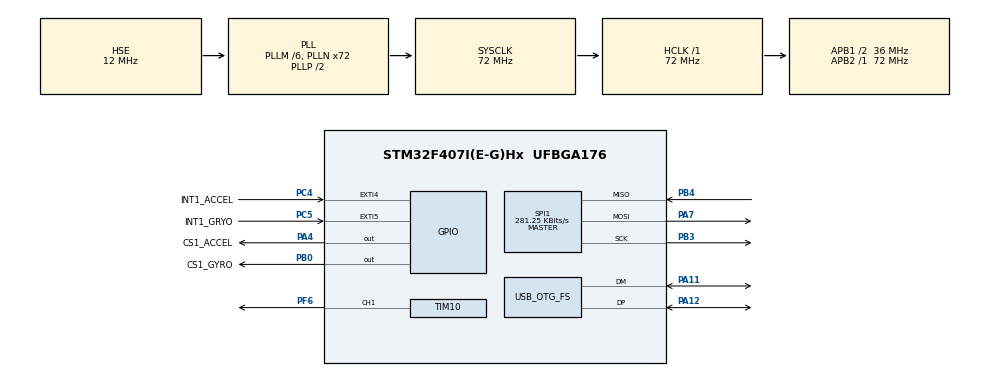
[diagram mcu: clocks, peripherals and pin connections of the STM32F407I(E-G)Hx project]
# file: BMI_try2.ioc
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Dma.Request0=SPI1_RX
Dma.Request1=SPI1_TX
Dma.SPI1_RX.0.Direction=DMA_PERIPH_TO_MEMORY
Dma.SPI1_RX.0.FIFOMode=DMA_FIFOMODE_DISABLE
Dma.SPI1_RX.0.Instance=DMA2_Stream2
Dma.SPI1_RX.0.MemDataAlignment=DMA_MDATAALIGN_BYTE
Dma.SPI1_RX.0.MemInc=DMA_MINC_ENABLE
Dma.SPI1_RX.0.Mode=DMA_NORMAL
Dma.SPI1_RX.0.PeriphDataAlignment=DMA_PDATAALIGN_BYTE
Dma.SPI1_RX.0.PeriphInc=DMA_PINC_DISABLE
Dma.SPI1_RX.0.Priority=DMA_PRIORITY_VERY_HIGH
Dma.SPI1_TX.1.Direction=DMA_MEMORY_TO_PERIPH
Dma.SPI1_TX.1.FIFOMode=DMA_FIFOMODE_DISABLE
Dma.SPI1_TX.1.Instance=DMA2_Stream3
Dma.SPI1_TX.1.MemDataAlignment=DMA_MDATAALIGN_BYTE
Dma.SPI1_TX.1.MemInc=DMA_MINC_ENABLE
Dma.SPI1_TX.1.Mode=DMA_NORMAL
Dma.SPI1_TX.1.PeriphDataAlignment=DMA_PDATAALIGN_BYTE
Dma.SPI1_TX.1.PeriphInc=DMA_PINC_DISABLE
Dma.SPI1_TX.1.Priority=DMA_PRIORITY_HIGH
FREERTOS.Tasks01=defaultTask,0,128,StartDefaultTask,Default,NULL,Dynamic,NULL,NULL;Usb_task,3,3072,usb_task,As weak,NULL,Dynamic,NULL,NULL
Mcu.Family=STM32F4
Mcu.Name=STM32F407I(E-G)Hx
Mcu.Package=UFBGA176
NVIC.DMA2_Stream2_IRQn=true\:5\:0\:false\:false\:true\:true\:false\:true\:true
NVIC.DMA2_Stream3_IRQn=true\:5\:0\:false\:false\:true\:true\:false\:true\:true
NVIC.OTG_FS_IRQn=true\:5\:0\:false\:false\:true\:true\:false\:true\:true
NVIC.PriorityGroup=NVIC_PRIORITYGROUP_4
NVIC.TIM1_UP_TIM10_IRQn=true\:15\:0\:false\:false\:true\:false\:false\:true\:true
NVIC.TimeBase=TIM1_UP_TIM10_IRQn
NVIC.TimeBaseIP=TIM1
PA11.Mode=Device_Only
PA11.Signal=USB_OTG_FS_DM
PA12.Mode=Device_Only
PA12.Signal=USB_OTG_FS_DP
PA13.Mode=Serial_Wire
PA13.Signal=SYS_JTMS-SWDIO
PA14.Mode=Serial_Wire
PA14.Signal=SYS_JTCK-SWCLK
PA4.GPIO_Label=CS1_ACCEL
PA4.GPIO_PuPd=GPIO_PULLUP
PA4.GPIO_Speed=GPIO_SPEED_FREQ_HIGH
PA4.PinState=GPIO_PIN_SET
PA4.Signal=GPIO_Output
PA7.Mode=Full_Duplex_Master
PA7.Signal=SPI1_MOSI
PB0.GPIO_Label=CS1_GYRO
PB0.GPIO_PuPd=GPIO_PULLUP
PB0.GPIO_Speed=GPIO_SPEED_FREQ_HIGH
PB0.PinState=GPIO_PIN_SET
PB0.Signal=GPIO_Output
PB3.Mode=Full_Duplex_Master
PB3.Signal=SPI1_SCK
PB4.Mode=Full_Duplex_Master
PB4.Signal=SPI1_MISO
PC4.GPIO_Label=INT1_ACCEL
PC4.GPIO_PuPd=GPIO_PULLUP
PC4.Signal=GPXTI4
PC5.GPIO_Label=INT1_GRYO
PC5.GPIO_PuPd=GPIO_PULLUP
PC5.Signal=GPXTI5
PF6.GPIO_PuPd=GPIO_PULLUP
PF6.GPIO_Speed=GPIO_SPEED_FREQ_HIGH
PF6.Signal=S_TIM10_CH1
PH0-OSC_IN.Mode=HSE-External-Oscillator
PH0-OSC_IN.Signal=RCC_OSC_IN
PH1-OSC_OUT.Mode=HSE-External-Oscillator
PH1-OSC_OUT.Signal=RCC_OSC_OUT
ProjectManager.HeapSize=0x200
ProjectManager.StackSize=0x400
ProjectManager.TargetToolchain=MDK-ARM V5.32
RCC.48MHZClocksFreq_Value=48000000
RCC.AHBFreq_Value=72000000
RCC.APB1CLKDivider=RCC_HCLK_DIV2
RCC.APB1Freq_Value=36000000
RCC.APB1TimFreq_Value=72000000
RCC.APB2Freq_Value=72000000
RCC.APB2TimFreq_Value=72000000
RCC.CortexFreq_Value=72000000
RCC.HCLKFreq_Value=72000000
RCC.HSE_VALUE=12000000
RCC.HSI_VALUE=16000000
RCC.LSE_VALUE=32768
RCC.PLLM=6
RCC.PLLN=72
RCC.PLLQ=3
RCC.SYSCLKFreq_VALUE=72000000
RCC.SYSCLKSource=RCC_SYSCLKSOURCE_PLLCLK
RCC.VCOOutputFreq_Value=144000000
SH.S_TIM10_CH1.0=TIM10_CH1,PWM Generation1 CH1
SPI1.BaudRatePrescaler=SPI_BAUDRATEPRESCALER_256
SPI1.CLKPhase=SPI_PHASE_2EDGE
SPI1.CLKPolarity=SPI_POLARITY_HIGH
SPI1.CalculateBaudRate=281.25 KBits/s
SPI1.Direction=SPI_DIRECTION_2LINES
SPI1.Mode=SPI_MODE_MASTER
SPI1.VirtualType=VM_MASTER
TIM10.Channel=TIM_CHANNEL_1
TIM10.Period=4999
USB_DEVICE.CLASS_NAME_FS=CDC
USB_DEVICE.MANUFACTURER_STRING-CDC_FS=RM
USB_DEVICE.PID_CDC_FS=0x514
USB_DEVICE.VID-CDC_FS=0x114
USB_DEVICE.VirtualMode-CDC_FS=Cdc
USB_DEVICE.VirtualModeFS=Cdc_FS
USB_OTG_FS.VirtualMode=Device_Only
VP_FREERTOS_VS_CMSIS_V1.Mode=CMSIS_V1
VP_SYS_VS_tim1.Mode=TIM1
VP_TIM10_VS_ClockSourceINT.Mode=Enable_Timer
VP_USB_DEVICE_VS_USB_DEVICE_CDC_FS.Mode=CDC_FS
board=custom

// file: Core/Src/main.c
/* USER CODE BEGIN Header */
/**
  ******************************************************************************
  * @file           : main.c
  * @brief          : Main program body
  ******************************************************************************
  * @attention
  *
  * Copyright (c) 2026 STMicroelectronics.
  * All rights reserved.
  *
  * This software is licensed under terms that can be found in the LICENSE file
  * in the root directory of this software component.
  * If no LICENSE file comes with this software, it is provided AS-IS.
  *
  ******************************************************************************
  */
/* USER CODE END Header */
#include "main.h"
#include "cmsis_os.h"
#include "dma.h"
#include "spi.h"
#include "tim.h"
#include "usb_device.h"
#include "gpio.h"

/* USER CODE BEGIN Includes */
#include "bsp_usb.h"
#include "queue.h"
#include "BMI088Middleware.h"
#include "struct_typedef.h"
#include "BMI088driver.h"
#include "usbd_cdc_if.h"
/* USER CODE END Includes */

void SystemClock_Config(void);
void MX_FREERTOS_Init(void);
/* USER CODE BEGIN PFP */
uint8_t usb_tx_buf[128];
uint8_t usb_rx_buf[128];
/* USER CODE END PFP */

int main(void)
{

  /* MCU Configuration--------------------------------------------------------*/

  /* Reset of all peripherals, Initializes the Flash interface and the Systick. */
  HAL_Init();

  /* Configure the system clock */
  SystemClock_Config();

  /* Initialize all configured peripherals */
  MX_GPIO_Init();
  MX_DMA_Init();
  MX_SPI1_Init();
  MX_TIM10_Init();
  /* USER CODE BEGIN 2 */
	usb_init();
 MX_USB_DEVICE_Init();
  /* USER CODE END 2 */

  /* Call init function for freertos objects (in cmsis_os2.c) */
  MX_FREERTOS_Init();

  /* Start scheduler */
  osKernelStart();

  /* We should never get here as control is now taken by the scheduler */

  /* Infinite loop */
  while (1)
  {

  }
}

void SystemClock_Config(void)
{
  RCC_OscInitTypeDef RCC_OscInitStruct = {0};
  RCC_ClkInitTypeDef RCC_ClkInitStruct = {0};

  /** Configure the main internal regulator output voltage
  */
  __HAL_RCC_PWR_CLK_ENABLE();
  __HAL_PWR_VOLTAGESCALING_CONFIG(PWR_REGULATOR_VOLTAGE_SCALE1);

  /** Initializes the RCC Oscillators according to the specified parameters
  * in the RCC_OscInitTypeDef structure.
  */
  RCC_OscInitStruct.OscillatorType = RCC_OSCILLATORTYPE_HSE;
  RCC_OscInitStruct.HSEState = RCC_HSE_ON;
  RCC_OscInitStruct.PLL.PLLState = RCC_PLL_ON;
  RCC_OscInitStruct.PLL.PLLSource = RCC_PLLSOURCE_HSE;
  RCC_OscInitStruct.PLL.PLLM = 6;
  RCC_OscInitStruct.PLL.PLLN = 72;
  RCC_OscInitStruct.PLL.PLLP = RCC_PLLP_DIV2;
  RCC_OscInitStruct.PLL.PLLQ = 3;
  if (HAL_RCC_OscConfig(&RCC_OscInitStruct) != HAL_OK)
  {
    Error_Handler();
  }

  /** Initializes the CPU, AHB and APB buses clocks
  */
  RCC_ClkInitStruct.ClockType = RCC_CLOCKTYPE_HCLK|RCC_CLOCKTYPE_SYSCLK
                              |RCC_CLOCKTYPE_PCLK1|RCC_CLOCKTYPE_PCLK2;
  RCC_ClkInitStruct.SYSCLKSource = RCC_SYSCLKSOURCE_PLLCLK;
  RCC_ClkInitStruct.AHBCLKDivider = RCC_SYSCLK_DIV1;
  RCC_ClkInitStruct.APB1CLKDivider = RCC_HCLK_DIV2;
  RCC_ClkInitStruct.APB2CLKDivider = RCC_HCLK_DIV1;

  if (HAL_RCC_ClockConfig(&RCC_ClkInitStruct, FLASH_LATENCY_2) != HAL_OK)
  {
    Error_Handler();
  }
}

void HAL_TIM_PeriodElapsedCallback(TIM_HandleTypeDef *htim)
{
  if (htim->Instance == TIM1)
  {
    HAL_IncTick();
  }
}

void Error_Handler(void)
{
  __disable_irq();
  while (1)
  {
  }
}
